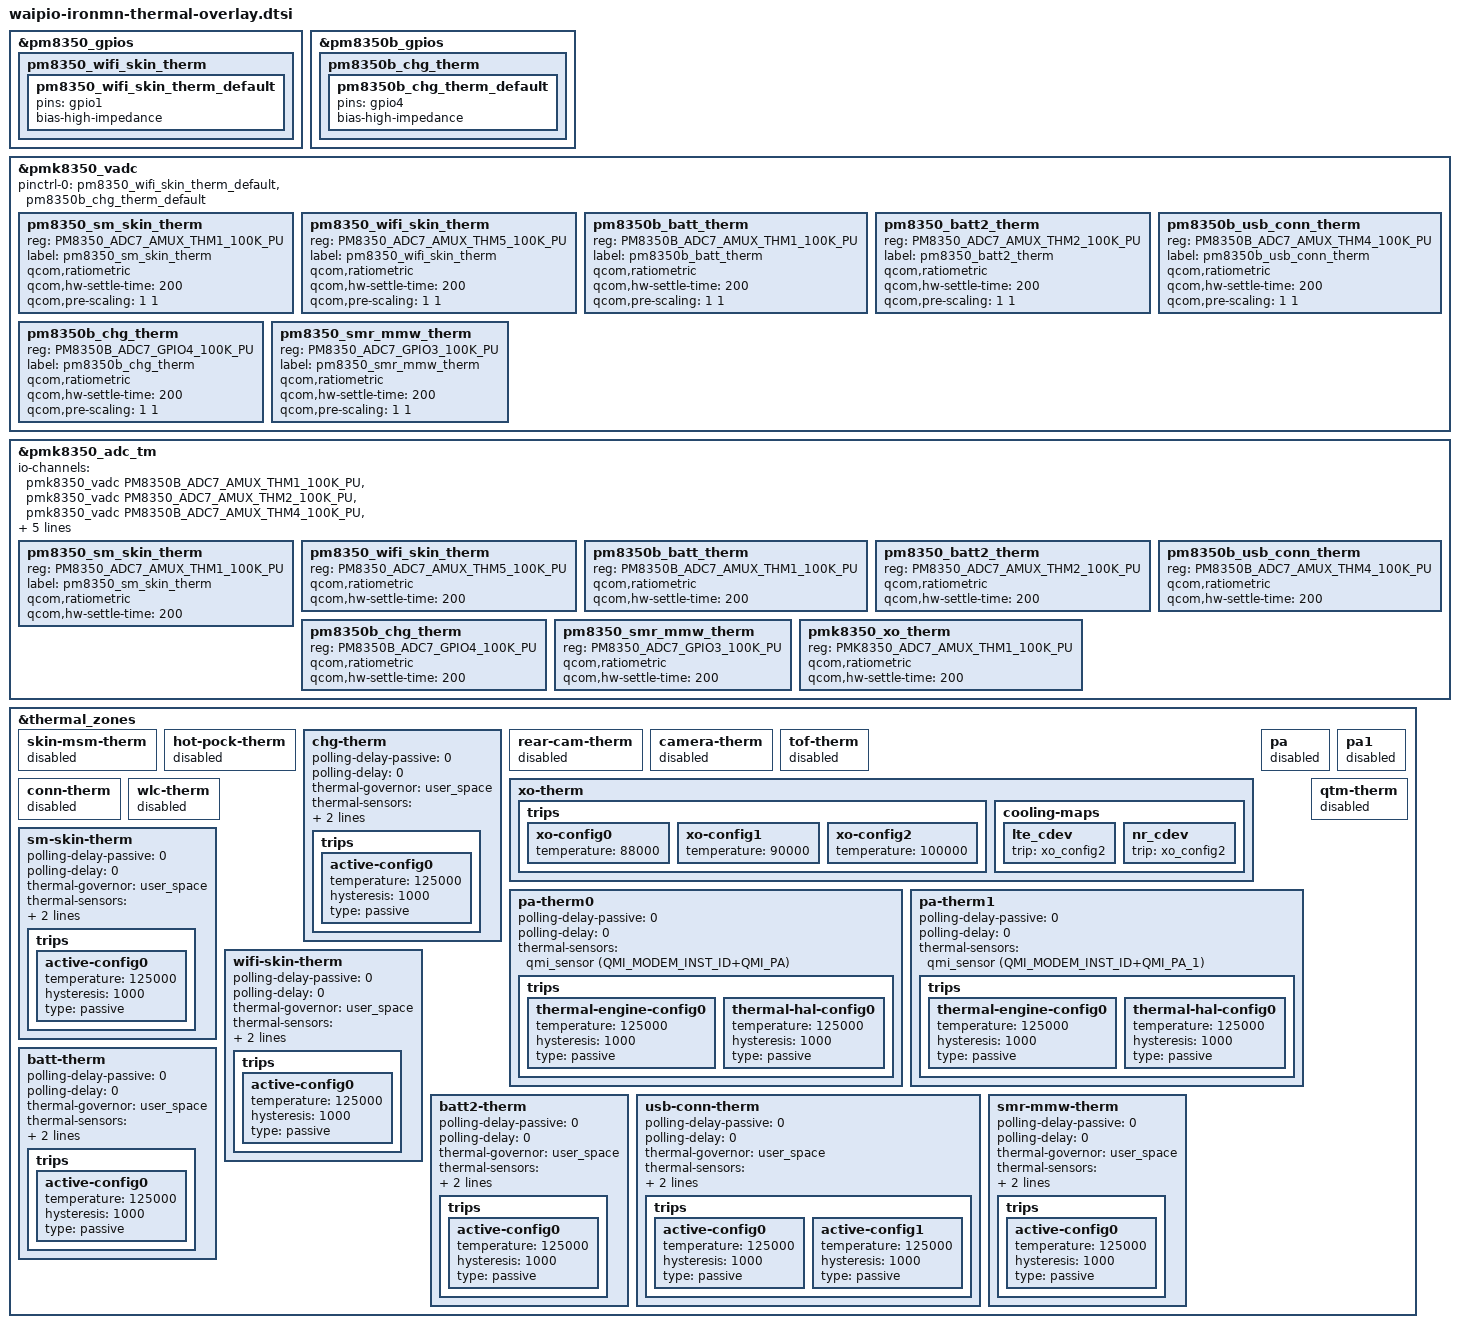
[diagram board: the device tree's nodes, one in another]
#include "moto_therm_sys_temp.dtsi"


&pm8350_gpios {
	/delete-node/ pm8350_rear_tof_therm;

	pm8350_wifi_skin_therm {
		pm8350_wifi_skin_therm_default: pm8350_wifi_skin_therm_default {
			pins = "gpio1";
			bias-high-impedance;
		};
	};
};

&pm8350b_gpios {
	pm8350b_chg_therm {
		pm8350b_chg_therm_default: pm8350b_chg_therm_default {
			pins = "gpio4";
			bias-high-impedance;
		};
	};
};

&pmk8350_vadc {
	pinctrl-names = "default";
	pinctrl-0 = <&pm8350_wifi_skin_therm_default &pm8350b_chg_therm_default>;

	/delete-node/ pm8350_msm_therm;
	/delete-node/ pm8350_cam_flash_therm;
	/delete-node/ pm8350_hot_pocket_therm;
	/delete-node/ pm8350_wide_rfc_therm;
	/delete-node/ pm8350_rear_tof_therm;
	/delete-node/ pm8350b_wl_chg_therm;
	/delete-node/ pm8350b_usb_conn_therm;

	pm8350_sm_skin_therm {
		reg = <PM8350_ADC7_AMUX_THM1_100K_PU>;
		label = "pm8350_sm_skin_therm";
		qcom,ratiometric;
		qcom,hw-settle-time = <200>;
		qcom,pre-scaling = <1 1>;
	};

	pm8350_wifi_skin_therm {
		reg = <PM8350_ADC7_AMUX_THM5_100K_PU>;
		label = "pm8350_wifi_skin_therm";
		qcom,ratiometric;
		qcom,hw-settle-time = <200>;
		qcom,pre-scaling = <1 1>;
	};

	pm8350b_batt_therm {
		reg = <PM8350B_ADC7_AMUX_THM1_100K_PU>;
		label = "pm8350b_batt_therm";
		qcom,ratiometric;
		qcom,hw-settle-time = <200>;
		qcom,pre-scaling = <1 1>;
	};

	pm8350_batt2_therm {
		reg = <PM8350_ADC7_AMUX_THM2_100K_PU>;
		label = "pm8350_batt2_therm";
		qcom,ratiometric;
		qcom,hw-settle-time = <200>;
		qcom,pre-scaling = <1 1>;
	};

	pm8350b_usb_conn_therm {
		reg = <PM8350B_ADC7_AMUX_THM4_100K_PU>;
		label = "pm8350b_usb_conn_therm";
		qcom,ratiometric;
		qcom,hw-settle-time = <200>;
		qcom,pre-scaling = <1 1>;
	};

	pm8350b_chg_therm {
		reg = <PM8350B_ADC7_GPIO4_100K_PU>;
		label = "pm8350b_chg_therm";
		qcom,ratiometric;
		qcom,hw-settle-time = <200>;
		qcom,pre-scaling = <1 1>;
	};

	pm8350_smr_mmw_therm {
		reg = <PM8350_ADC7_GPIO3_100K_PU>;
		label = "pm8350_smr_mmw_therm";
		qcom,ratiometric;
		qcom,hw-settle-time = <200>;
		qcom,pre-scaling = <1 1>;
	};
};

&pmk8350_adc_tm {
	io-channels =
		<&pmk8350_vadc PM8350B_ADC7_AMUX_THM1_100K_PU>,
		<&pmk8350_vadc PM8350_ADC7_AMUX_THM2_100K_PU>,
		<&pmk8350_vadc PM8350B_ADC7_AMUX_THM4_100K_PU>,
		<&pmk8350_vadc PM8350B_ADC7_GPIO4_100K_PU>,
		<&pmk8350_vadc PM8350_ADC7_AMUX_THM1_100K_PU>,
		<&pmk8350_vadc PM8350_ADC7_AMUX_THM5_100K_PU>,
		<&pmk8350_vadc PM8350_ADC7_GPIO3_100K_PU>,
		<&pmk8350_vadc PMK8350_ADC7_AMUX_THM1_100K_PU>;

	/delete-node/ pm8350_msm_therm;
	/delete-node/ pm8350_cam_flash_therm;
	/delete-node/ pm8350_hot_pocket_therm;
	/delete-node/ pm8350_wide_rfc_therm;
	/delete-node/ pm8350_rear_tof_therm;
	/delete-node/ pm8350b_wl_chg_therm;

	/delete-node/ pm8350b_usb_conn_therm;

	pm8350_sm_skin_therm {
		reg = <PM8350_ADC7_AMUX_THM1_100K_PU>;
		label = "pm8350_sm_skin_therm";
		qcom,ratiometric;
		qcom,hw-settle-time = <200>;
	};

	pm8350_wifi_skin_therm {
		reg = <PM8350_ADC7_AMUX_THM5_100K_PU>;
		qcom,ratiometric;
		qcom,hw-settle-time = <200>;
	};

	pm8350b_batt_therm {
		reg = <PM8350B_ADC7_AMUX_THM1_100K_PU>;
		qcom,ratiometric;
		qcom,hw-settle-time = <200>;
	};

	pm8350_batt2_therm {
		reg = <PM8350_ADC7_AMUX_THM2_100K_PU>;
		qcom,ratiometric;
		qcom,hw-settle-time = <200>;
	};

	pm8350b_usb_conn_therm {
		reg = <PM8350B_ADC7_AMUX_THM4_100K_PU>;
		qcom,ratiometric;
		qcom,hw-settle-time = <200>;
	};

	pm8350b_chg_therm {
		reg = <PM8350B_ADC7_GPIO4_100K_PU>;
		qcom,ratiometric;
		qcom,hw-settle-time = <200>;
	};

	pm8350_smr_mmw_therm {
		reg = <PM8350_ADC7_GPIO3_100K_PU>;
		qcom,ratiometric;
		qcom,hw-settle-time = <200>;
	};

	pmk8350_xo_therm {
		reg = <PMK8350_ADC7_AMUX_THM1_100K_PU>;
		qcom,ratiometric;
		qcom,hw-settle-time = <200>;
	};
};

&thermal_zones {
	skin-msm-therm {
		status = "disabled";
	};

	hot-pock-therm {
		status = "disabled";
	};

	chg-therm {
		polling-delay-passive = <0>;
		polling-delay = <0>;
		thermal-governor = "user_space";
		thermal-sensors = <&pmk8350_adc_tm PM8350B_ADC7_GPIO4_100K_PU>;
		wake-capable-sensor;
		trips {
			active-config0 {
				temperature = <125000>;
				hysteresis = <1000>;
				type = "passive";
			};
		};
	};

	rear-cam-therm {
		status = "disabled";
	};
	camera-therm {
		status = "disabled";
	};
	tof-therm {
		status = "disabled";
	};

	xo-therm {
		trips {
			xo-config0 {
				temperature = <88000>;
			};

			xo-config1 {
				temperature = <90000>;
			};

			xo-config2 {
				temperature = <100000>;
			};
		};
		cooling-maps {
			lte_cdev {
				trip = <&xo_config2>;
			};
			nr_cdev {
				trip = <&xo_config2>;
			};
		};
	};

	pa {
		status = "disabled";
	};
	pa-therm0 {
		polling-delay-passive = <0>;
		polling-delay = <0>;
		thermal-sensors = <&qmi_sensor
				(QMI_MODEM_INST_ID+QMI_PA)>;
		trips {
			thermal-engine-config0 {
				temperature = <125000>;
				hysteresis = <1000>;
				type = "passive";
			};

			thermal-hal-config0 {
				temperature = <125000>;
				hysteresis = <1000>;
				type = "passive";
			};
		};
	};

	pa1 {
		status = "disabled";
	};

	pa-therm1 {
		polling-delay-passive = <0>;
		polling-delay = <0>;
		thermal-sensors = <&qmi_sensor
				(QMI_MODEM_INST_ID+QMI_PA_1)>;
		trips {
			thermal-engine-config0 {
				temperature = <125000>;
				hysteresis = <1000>;
				type = "passive";
			};

			thermal-hal-config0 {
				temperature = <125000>;
				hysteresis = <1000>;
				type = "passive";
			};
		};
	};

	conn-therm {
		status = "disabled";
	};

	wlc-therm {
		status = "disabled";
	};

	qtm-therm {
		status = "disabled";
	};

	sm-skin-therm {
		polling-delay-passive = <0>;
		polling-delay = <0>;
		thermal-governor = "user_space";
		thermal-sensors = <&pmk8350_adc_tm PM8350_ADC7_AMUX_THM1_100K_PU>;
		wake-capable-sensor;
		trips {
			active-config0 {
				temperature = <125000>;
				hysteresis = <1000>;
				type = "passive";
			};
		};
	};

	wifi-skin-therm {
		polling-delay-passive = <0>;
		polling-delay = <0>;
		thermal-governor = "user_space";
		thermal-sensors = <&pmk8350_adc_tm PM8350_ADC7_AMUX_THM5_100K_PU>;
		wake-capable-sensor;
		trips {
			active-config0 {
				temperature = <125000>;
				hysteresis = <1000>;
				type = "passive";
			};
		};
	};

	batt-therm {
		polling-delay-passive = <0>;
		polling-delay = <0>;
		thermal-governor = "user_space";
		thermal-sensors = <&pmk8350_adc_tm PM8350B_ADC7_AMUX_THM1_100K_PU>;
		wake-capable-sensor;
		trips {
			active-config0 {
				temperature = <125000>;
				hysteresis = <1000>;
				type = "passive";
			};
		};
	};

	batt2-therm {
		polling-delay-passive = <0>;
		polling-delay = <0>;
		thermal-governor = "user_space";
		thermal-sensors = <&pmk8350_adc_tm PM8350_ADC7_AMUX_THM2_100K_PU>;
		wake-capable-sensor;
		trips {
			active-config0 {
				temperature = <125000>;
				hysteresis = <1000>;
				type = "passive";
			};
		};
	};

	usb-conn-therm {
		polling-delay-passive = <0>;
		polling-delay = <0>;
		thermal-governor = "user_space";
		thermal-sensors = <&pmk8350_adc_tm PM8350B_ADC7_AMUX_THM4_100K_PU>;
		wake-capable-sensor;
		trips {
			active-config0 {
				temperature = <125000>;
				hysteresis = <1000>;
				type = "passive";
			};

			active-config1 {
				temperature = <125000>;
				hysteresis = <1000>;
				type = "passive";
			};
		};
	};

	smr-mmw-therm {
		polling-delay-passive = <0>;
		polling-delay = <0>;
		thermal-governor = "user_space";
		thermal-sensors = <&pmk8350_adc_tm PM8350_ADC7_GPIO3_100K_PU>;
		wake-capable-sensor;
		trips {
			active-config0 {
				temperature = <125000>;
				hysteresis = <1000>;
				type = "passive";
			};
		};
	};
};
